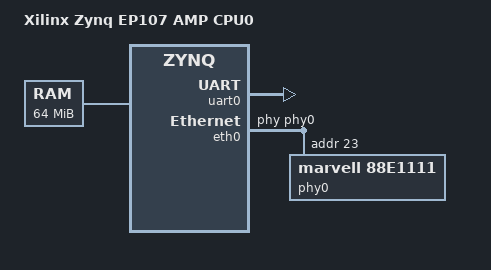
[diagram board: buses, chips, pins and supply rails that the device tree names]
/*
 *  Copyright (C) 2011 Xilinx
 *
 * This software is licensed under the terms of the GNU General Public
 * License version 2, as published by the Free Software Foundation, and
 * may be copied, distributed, and modified under those terms.
 *
 * This program is distributed in the hope that it will be useful,
 * but WITHOUT ANY WARRANTY; without even the implied warranty of
 * MERCHANTABILITY or FITNESS FOR A PARTICULAR PURPOSE.  See the
 * GNU General Public License for more details.
 */

/dts-v1/;

/ {
	model = "Xilinx Zynq EP107 AMP CPU0";
	compatible = "xlnx,zynq-ep107";
	#address-cells = <1>;
	#size-cells = <1>;
	interrupt-parent = <&intc>;

	memory {
		device_type = "memory";
		reg = <0x400000 0x4000000>;
   	};

	chosen {
		bootargs = "console=ttyPS0,115200 root=/dev/ram rw initrd=0x800000,8M earlyprintk";
		linux,stdout-path = "/amba@0/uart@E0000000";
	};

	amba: amba@0 {
		compatible = "simple-bus";
		#address-cells = <1>;
		#size-cells = <1>;
		ranges;

		intc: intc@f8f01000 {
			interrupt-controller;
			compatible = "arm,gic";
			reg = <0xF8F01000 0x1000>;
			#interrupt-cells = <2>;
		};

		uart0: uart@e0000000 {
			compatible = "xlnx,ps7-uart-1.00.a";
			reg = <0xE0000000 0x1000>;
			interrupts = <59 0>;
			clock = <50000000>;
		};
	
		eth0: eth@e000b000 {
			compatible = "xlnx,ps7-ethernet-1.00.a";
			reg = <0xE000B000 0x1000>;
			interrupts = <54 0>;
			phy-handle = <&phy0>;
			#address-cells = <1>;
			#size-cells = <0>;
			phy0: phy@23 {
				compatible = "marvell,88e1111";
				device_type = "ethernet-phy";
				reg = <23>;
			} ;
		};
	};
};
